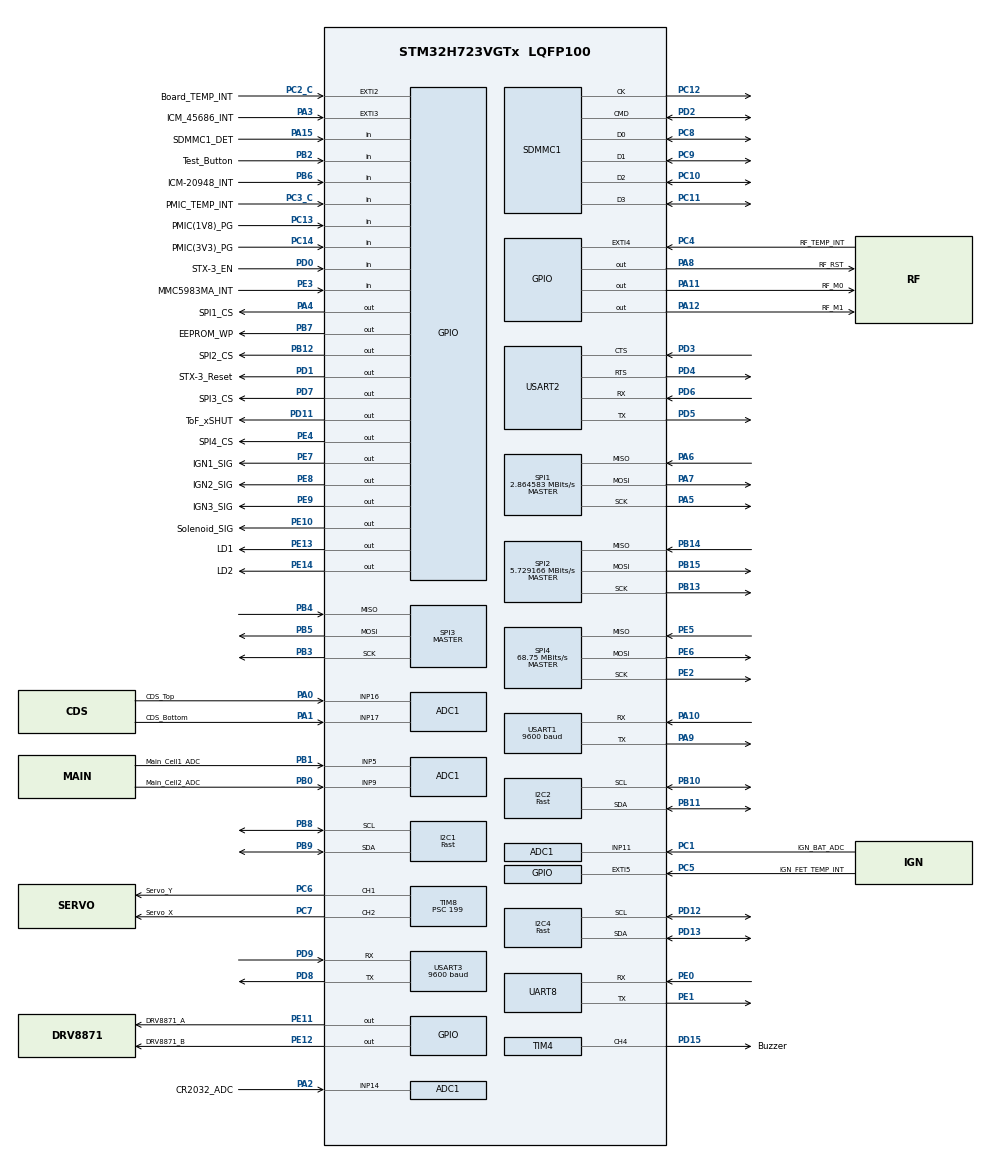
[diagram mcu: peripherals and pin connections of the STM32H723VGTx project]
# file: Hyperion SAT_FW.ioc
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ADC1.Channel-1\#ChannelRegularConversion=ADC_CHANNEL_5
ADC1.Channel-2\#ChannelRegularConversion=ADC_CHANNEL_9
ADC1.Channel-3\#ChannelRegularConversion=ADC_CHANNEL_11
ADC1.Channel-4\#ChannelRegularConversion=ADC_CHANNEL_14
ADC1.Channel-5\#ChannelRegularConversion=ADC_CHANNEL_16
ADC1.Channel-6\#ChannelRegularConversion=ADC_CHANNEL_17
ADC1.ClockPrescaler=ADC_CLOCK_ASYNC_DIV4
ADC1.ClockPrescalerADC3=ADC_CLOCK_ASYNC_DIV4
ADC1.ContinuousConvMode=ENABLE
ADC1.ConversionDataManagement=ADC_CONVERSIONDATA_DMA_CIRCULAR
ADC1.NbrOfConversion=6
ADC1.NbrOfConversionFlag=1
ADC1.OffsetNumber-1\#ChannelRegularConversion=ADC_OFFSET_NONE
ADC1.OffsetNumber-2\#ChannelRegularConversion=ADC_OFFSET_NONE
ADC1.OffsetNumber-3\#ChannelRegularConversion=ADC_OFFSET_NONE
ADC1.OffsetNumber-4\#ChannelRegularConversion=ADC_OFFSET_NONE
ADC1.OffsetNumber-5\#ChannelRegularConversion=ADC_OFFSET_NONE
ADC1.OffsetNumber-6\#ChannelRegularConversion=ADC_OFFSET_NONE
ADC1.OffsetSignedSaturation-1\#ChannelRegularConversion=DISABLE
ADC1.OffsetSignedSaturation-2\#ChannelRegularConversion=DISABLE
ADC1.OffsetSignedSaturation-3\#ChannelRegularConversion=DISABLE
ADC1.OffsetSignedSaturation-4\#ChannelRegularConversion=DISABLE
ADC1.OffsetSignedSaturation-5\#ChannelRegularConversion=DISABLE
ADC1.OffsetSignedSaturation-6\#ChannelRegularConversion=DISABLE
ADC1.Rank-1\#ChannelRegularConversion=1
ADC1.Rank-2\#ChannelRegularConversion=2
ADC1.Rank-3\#ChannelRegularConversion=3
ADC1.Rank-4\#ChannelRegularConversion=4
ADC1.Rank-5\#ChannelRegularConversion=5
ADC1.Rank-6\#ChannelRegularConversion=6
ADC1.SamplingTime-1\#ChannelRegularConversion=ADC_SAMPLETIME_387CYCLES_5
ADC1.SamplingTime-2\#ChannelRegularConversion=ADC_SAMPLETIME_387CYCLES_5
ADC1.SamplingTime-3\#ChannelRegularConversion=ADC_SAMPLETIME_387CYCLES_5
ADC1.SamplingTime-4\#ChannelRegularConversion=ADC_SAMPLETIME_387CYCLES_5
ADC1.SamplingTime-5\#ChannelRegularConversion=ADC_SAMPLETIME_387CYCLES_5
ADC1.SamplingTime-6\#ChannelRegularConversion=ADC_SAMPLETIME_387CYCLES_5
ADC1.master=1
ADC3.Channel-0\#ChannelRegularConversion=ADC_CHANNEL_TEMPSENSOR
ADC3.Channel-1\#ChannelRegularConversion=ADC_CHANNEL_VREFINT
ADC3.ClockPrescaler=ADC_CLOCK_ASYNC_DIV4
ADC3.ClockPrescalerADC3=ADC_CLOCK_ASYNC_DIV4
ADC3.ContinuousConvMode=ENABLE
ADC3.ConversionDataManagement=ADC_CONVERSIONDATA_DMA_CIRCULAR
ADC3.DMAContinuousRequests=ENABLE
ADC3.NbrOfConversion=2
ADC3.NbrOfConversionFlag=1
ADC3.OffsetNumber-0\#ChannelRegularConversion=ADC_OFFSET_NONE
ADC3.OffsetNumber-1\#ChannelRegularConversion=ADC_OFFSET_NONE
ADC3.OffsetSign-0\#ChannelRegularConversion=ADC3_OFFSET_SIGN_NEGATIVE
ADC3.OffsetSign-1\#ChannelRegularConversion=ADC3_OFFSET_SIGN_NEGATIVE
ADC3.Rank-0\#ChannelRegularConversion=1
ADC3.Rank-1\#ChannelRegularConversion=2
ADC3.SamplingTime-0\#ChannelRegularConversion=ADC3_SAMPLETIME_640CYCLES_5
ADC3.SamplingTime-1\#ChannelRegularConversion=ADC3_SAMPLETIME_640CYCLES_5
CORTEX_M7.CPU_DCache=Disabled
CORTEX_M7.CPU_ICache=Disabled
CORTEX_M7.MPU_Control=MPU_PRIVILEGED_DEFAULT
CORTEX_M7.default_mode_Activation=1
Dma.ADC1.0.Direction=DMA_PERIPH_TO_MEMORY
Dma.ADC1.0.EventEnable=DISABLE
Dma.ADC1.0.FIFOMode=DMA_FIFOMODE_DISABLE
Dma.ADC1.0.Instance=DMA1_Stream0
Dma.ADC1.0.MemDataAlignment=DMA_MDATAALIGN_HALFWORD
Dma.ADC1.0.MemInc=DMA_MINC_ENABLE
Dma.ADC1.0.Mode=DMA_CIRCULAR
Dma.ADC1.0.PeriphDataAlignment=DMA_PDATAALIGN_HALFWORD
Dma.ADC1.0.PeriphInc=DMA_PINC_DISABLE
Dma.ADC1.0.Polarity=HAL_DMAMUX_REQ_GEN_RISING
Dma.ADC1.0.Priority=DMA_PRIORITY_LOW
Dma.ADC1.0.RequestNumber=1
Dma.ADC1.0.SignalID=NONE
Dma.ADC1.0.SyncEnable=DISABLE
Dma.ADC1.0.SyncPolarity=HAL_DMAMUX_SYNC_NO_EVENT
Dma.ADC1.0.SyncRequestNumber=1
Dma.ADC1.0.SyncSignalID=NONE
Dma.ADC3.1.Direction=DMA_PERIPH_TO_MEMORY
Dma.ADC3.1.EventEnable=DISABLE
Dma.ADC3.1.FIFOMode=DMA_FIFOMODE_DISABLE
Dma.ADC3.1.Instance=DMA1_Stream1
Dma.ADC3.1.MemDataAlignment=DMA_MDATAALIGN_HALFWORD
Dma.ADC3.1.MemInc=DMA_MINC_ENABLE
Dma.ADC3.1.Mode=DMA_CIRCULAR
Dma.ADC3.1.PeriphDataAlignment=DMA_PDATAALIGN_HALFWORD
Dma.ADC3.1.PeriphInc=DMA_PINC_DISABLE
Dma.ADC3.1.Polarity=HAL_DMAMUX_REQ_GEN_RISING
Dma.ADC3.1.Priority=DMA_PRIORITY_LOW
Dma.ADC3.1.RequestNumber=1
Dma.ADC3.1.SignalID=NONE
Dma.ADC3.1.SyncEnable=DISABLE
Dma.ADC3.1.SyncPolarity=HAL_DMAMUX_SYNC_NO_EVENT
Dma.ADC3.1.SyncRequestNumber=1
Dma.ADC3.1.SyncSignalID=NONE
Dma.Request0=ADC1
Dma.Request1=ADC3
FATFS.BSP.number=1
FATFS.USE_DMA_CODE_SD=1
FATFS._MAX_SS=512
FATFS._USE_LFN=2
FATFS0.BSP.STBoard=false
FATFS0.BSP.api=Unknown
FATFS0.BSP.instance=PA15(JTDI)
FATFS0.BSP.ip=GPIO
FATFS0.BSP.mode=Input
FATFS0.BSP.name=Detect_SDIO
FATFS0.BSP.solution=PA15(JTDI)
FREERTOS.Tasks01=BootTask,24,512,StartBootTask,Default,NULL,Dynamic,NULL,NULL;sendDataTask,8,512,StartsendDataTask,Default,NULL,Dynamic,NULL,NULL;ADC_Task,8,128,StartADC_Task,Default,NULL,Dynamic,NULL,NULL;IMU_Task,24,256,StartIMU_Task,Default,NULL,Dynamic,NULL,NULL;GPS_Task,24,256,StartGPS_Task,Default,NULL,Dynamic,NULL,NULL;MS5611_Task,16,256,StartMS5611_Task,Default,NULL,Dynamic,NULL,NULL;INA219_Task,8,128,StartINA219_Task,Default,NULL,Dynamic,NULL,NULL;ReadTemp_Task,8,256,StartReadTemp_Task,Default,NULL,Dynamic,NULL,NULL;MainTask,40,1024,StartMainTask,Default,NULL,Dynamic,NULL,NULL
FREERTOS.configUSE_NEWLIB_REENTRANT=1
I2C1.I2C_Speed_Mode=I2C_Fast
I2C1.Timing=0x00D049FB
I2C2.CustomTiming=Disabled
I2C2.I2C_Speed_Mode=I2C_Fast
I2C2.Timing=0x00D049FB
I2C4.I2C_Speed_Mode=I2C_Fast
I2C4.Timing=0x00D049FB
Mcu.Family=STM32H7
Mcu.Name=STM32H723VGTx
Mcu.Package=LQFP100
NVIC.DMA1_Stream0_IRQn=true\:5\:0\:false\:false\:true\:true\:false\:true\:true
NVIC.DMA1_Stream1_IRQn=true\:5\:0\:false\:false\:true\:true\:false\:true\:true
NVIC.EXTI3_IRQn=true\:5\:0\:false\:true\:true\:1\:true\:true\:true\:true
NVIC.PriorityGroup=NVIC_PRIORITYGROUP_4
NVIC.SDMMC1_IRQn=true\:5\:0\:false\:false\:true\:true\:true\:true\:true
NVIC.TIM6_DAC_IRQn=true\:15\:0\:false\:false\:true\:false\:false\:true\:true
NVIC.TimeBase=TIM6_DAC_IRQn
NVIC.TimeBaseIP=TIM6
NVIC.USART1_IRQn=true\:10\:0\:true\:true\:true\:3\:true\:true\:true\:true
NVIC.USART3_IRQn=true\:6\:0\:true\:true\:true\:2\:true\:true\:true\:true
PA0.GPIO_Label=CDS_Top
PA0.Mode=IN16-Single-Ended
PA0.Signal=ADC1_INP16
PA1.GPIO_Label=CDS_Bottom
PA1.Mode=IN17-Single-Ended
PA1.Signal=ADC1_INP17
PA10.Mode=Asynchronous
PA10.Signal=USART1_RX
PA11.GPIO_Label=RF_M0
PA11.Signal=GPIO_Output
PA12.GPIO_Label=RF_M1
PA12.Signal=GPIO_Output
PA13(JTMS/SWDIO).Mode=Serial_Wire
PA13(JTMS/SWDIO).Signal=DEBUG_JTMS-SWDIO
PA14(JTCK/SWCLK).Mode=Serial_Wire
PA14(JTCK/SWCLK).Signal=DEBUG_JTCK-SWCLK
PA15(JTDI).GPIO_Label=SDMMC1_DET
PA15(JTDI).Signal=GPIO_Input
PA2.GPIO_Label=CR2032_ADC
PA2.Signal=ADCx_INP14
PA3.GPIO_Label=ICM_45686_INT
PA3.GPIO_ModeDefaultEXTI=GPIO_MODE_IT_FALLING
PA3.Signal=GPXTI3
PA4.GPIO_Label=SPI1_CS
PA4.GPIO_PuPd=GPIO_PULLUP
PA4.GPIO_Speed=GPIO_SPEED_FREQ_HIGH
PA4.PinState=GPIO_PIN_SET
PA4.Signal=GPIO_Output
PA5.GPIO_Speed=GPIO_SPEED_FREQ_HIGH
PA5.Mode=Full_Duplex_Master
PA5.Signal=SPI1_SCK
PA6.GPIO_Speed=GPIO_SPEED_FREQ_HIGH
PA6.Mode=Full_Duplex_Master
PA6.Signal=SPI1_MISO
PA7.GPIO_Speed=GPIO_SPEED_FREQ_HIGH
PA7.Mode=Full_Duplex_Master
PA7.Signal=SPI1_MOSI
PA8.GPIO_Label=RF_RST
PA8.Signal=GPIO_Output
PA9.Mode=Asynchronous
PA9.Signal=USART1_TX
PB0.GPIO_Label=Main_Cell2_ADC
PB0.Signal=ADCx_INP9
PB1.GPIO_Label=Main_Cell1_ADC
PB1.Signal=ADCx_INP5
PB10.GPIO_Pu=GPIO_PULLUP
PB10.GPIO_Speed=GPIO_SPEED_FREQ_HIGH
PB10.Mode=I2C
PB10.Signal=I2C2_SCL
PB11.GPIO_Pu=GPIO_PULLUP
PB11.GPIO_Speed=GPIO_SPEED_FREQ_HIGH
PB11.Mode=I2C
PB11.Signal=I2C2_SDA
PB12.GPIO_Label=SPI2_CS
PB12.GPIO_PuPd=GPIO_PULLUP
PB12.Signal=GPIO_Output
PB13.Mode=Full_Duplex_Master
PB13.Signal=SPI2_SCK
PB14.Mode=Full_Duplex_Master
PB14.Signal=SPI2_MISO
PB15.Mode=Full_Duplex_Master
PB15.Signal=SPI2_MOSI
PB2.GPIO_Label=Test_Button
PB2.Signal=GPIO_Input
PB3(JTDO/TRACESWO).Mode=Full_Duplex_Master
PB3(JTDO/TRACESWO).Signal=SPI3_SCK
PB4(NJTRST).Mode=Full_Duplex_Master
PB4(NJTRST).Signal=SPI3_MISO
PB5.Mode=Full_Duplex_Master
PB5.Signal=SPI3_MOSI
PB6.GPIO_Label=ICM-20948_INT
PB6.Signal=GPIO_Input
PB7.GPIO_Label=EEPROM_WP
PB7.PinState=GPIO_PIN_SET
PB7.Signal=GPIO_Output
PB8.Mode=I2C
PB8.Signal=I2C1_SCL
PB9.Mode=I2C
PB9.Signal=I2C1_SDA
PC1.GPIO_Label=IGN_BAT_ADC
PC1.Signal=ADCx_INP11
PC10.Mode=SD_4_bits_Wide_bus
PC10.Signal=SDMMC1_D2
PC11.Mode=SD_4_bits_Wide_bus
PC11.Signal=SDMMC1_D3
PC12.Mode=SD_4_bits_Wide_bus
PC12.Signal=SDMMC1_CK
PC13.GPIO_Label=PMIC(1V8)_PG
PC13.Signal=GPIO_Input
PC14-OSC32_IN.GPIO_Label=PMIC(3V3)_PG
PC14-OSC32_IN.Signal=GPIO_Input
PC2_C.GPIO_Label=Board_TEMP_INT
PC2_C.Signal=GPXTI2
PC3_C.GPIO_Label=PMIC_TEMP_INT
PC3_C.Signal=GPIO_Input
PC4.GPIO_Label=RF_TEMP_INT
PC4.Signal=GPXTI4
PC5.GPIO_Label=IGN_FET_TEMP_INT
PC5.Signal=GPXTI5
PC6.GPIO_Label=Servo_Y
PC6.Signal=S_TIM8_CH1
PC7.GPIO_Label=Servo_X
PC7.Signal=S_TIM8_CH2
PC8.Mode=SD_4_bits_Wide_bus
PC8.Signal=SDMMC1_D0
PC9.Mode=SD_4_bits_Wide_bus
PC9.Signal=SDMMC1_D1
PD0.GPIO_Label=STX-3_EN
PD0.Signal=GPIO_Input
PD1.GPIO_Label=STX-3_Reset
PD1.Signal=GPIO_Output
PD11.GPIO_Label=ToF_xSHUT
PD11.Signal=GPIO_Output
PD12.Mode=I2C
PD12.Signal=I2C4_SCL
PD13.Mode=I2C
PD13.Signal=I2C4_SDA
PD15.GPIO_Label=Buzzer
PD15.Signal=S_TIM4_CH4
PD2.Mode=SD_4_bits_Wide_bus
PD2.Signal=SDMMC1_CMD
PD3.Mode=CTS_RTS
PD3.Signal=USART2_CTS
PD4.Mode=CTS_RTS
PD4.Signal=USART2_RTS
PD5.Mode=Asynchronous
PD5.Signal=USART2_TX
PD6.Mode=Asynchronous
PD6.Signal=USART2_RX
PD7.GPIO_Label=SPI3_CS
PD7.Signal=GPIO_Output
PD8.Mode=Asynchronous
PD8.Signal=USART3_TX
PD9.Mode=Asynchronous
PD9.Signal=USART3_RX
PE0.Mode=Asynchronous
PE0.Signal=UART8_RX
PE1.Mode=Asynchronous
PE1.Signal=UART8_TX
PE10.GPIO_Label=Solenoid_SIG
PE10.Signal=GPIO_Output
PE11.GPIO_Label=DRV8871_A
PE11.Signal=GPIO_Output
PE12.GPIO_Label=DRV8871_B
PE12.Signal=GPIO_Output
PE13.GPIO_Label=LD1
PE13.Signal=GPIO_Output
PE14.GPIO_Label=LD2
PE14.Signal=GPIO_Output
PE2.Mode=Full_Duplex_Master
PE2.Signal=SPI4_SCK
PE3.GPIO_Label=MMC5983MA_INT
PE3.Signal=GPIO_Input
PE4.GPIO_Label=SPI4_CS
PE4.Signal=GPIO_Output
PE5.Mode=Full_Duplex_Master
PE5.Signal=SPI4_MISO
PE6.Mode=Full_Duplex_Master
PE6.Signal=SPI4_MOSI
PE7.GPIO_Label=IGN1_SIG
PE7.Signal=GPIO_Output
PE8.GPIO_Label=IGN2_SIG
PE8.Signal=GPIO_Output
PE9.GPIO_Label=IGN3_SIG
PE9.Signal=GPIO_Output
PH0-OSC_IN.Mode=HSE-External-Oscillator
PH0-OSC_IN.Signal=RCC_OSC_IN
PH1-OSC_OUT.Mode=HSE-External-Oscillator
PH1-OSC_OUT.Signal=RCC_OSC_OUT
ProjectManager.HeapSize=0x200
ProjectManager.StackSize=0x400
ProjectManager.TargetToolchain=STM32CubeIDE
RCC.ADCFreq_Value=96000000
RCC.APB1Freq_Value=137500000
RCC.APB2Freq_Value=137500000
RCC.APB3Freq_Value=137500000
RCC.APB4Freq_Value=137500000
RCC.CortexFreq_Value=550000000
RCC.D1PPRE=RCC_APB3_DIV2
RCC.D2PPRE1=RCC_APB1_DIV2
RCC.D2PPRE2=RCC_APB2_DIV2
RCC.D3PPRE=RCC_APB4_DIV2
RCC.DIVM1=3
RCC.DIVM2=1
RCC.DIVN1=137
RCC.DIVN2=16
RCC.DIVP1=1
RCC.DIVQ1=3
RCC.HCLKFreq_Value=275000000
RCC.HPRE=RCC_HCLK_DIV2
RCC.HSE_VALUE=12000000
RCC.PLL1_VCI_Range-AdvancedSettings=RCC_PLL1VCIRANGE_0
RCC.PLL1_VCO_SEL-AdvancedSettings=RCC_PLL1VCOMEDIUM
RCC.PLL2FRACN=0
RCC.PLL2_VCO_SEL-AdvancedSettings=RCC_PLL2VCOMEDIUM
RCC.PLL3FRACN=0
RCC.PLL3_VCO_SEL-AdvancedSettings=RCC_PLL3VCOMEDIUM
RCC.PLLFRACN=4096
RCC.PLLSourceVirtual=RCC_PLLSOURCE_HSE
RCC.SDMMC1CLockSelection=RCC_SDMMCCLKSOURCE_PLL2
RCC.SYSCLKFreq_VALUE=550000000
RCC.SYSCLKSource=RCC_SYSCLKSOURCE_PLLCLK
RCC.Tim1Mul=1
RCC.Tim2Mul=1
RCC.USBFreq_Value=183333333.33333334
SDMMC1.ClockDiv=2
SH.ADCx_INP11.0=ADC1_INP11,IN11-Single-Ended
SH.ADCx_INP14.0=ADC1_INP14,IN14-Single-Ended
SH.ADCx_INP5.0=ADC1_INP5,IN5-Single-Ended
SH.ADCx_INP9.0=ADC1_INP9,IN9-Single-Ended
SH.S_TIM4_CH4.0=TIM4_CH4,PWM Generation4 CH4
SH.S_TIM8_CH1.0=TIM8_CH1,PWM Generation1 CH1
SH.S_TIM8_CH2.0=TIM8_CH2,PWM Generation2 CH2
SPI1.BaudRatePrescaler=SPI_BAUDRATEPRESCALER_64
SPI1.CLKPhase=SPI_PHASE_2EDGE
SPI1.CLKPolarity=SPI_POLARITY_HIGH
SPI1.CalculateBaudRate=2.864583 MBits/s
SPI1.DataSize=SPI_DATASIZE_8BIT
SPI1.Direction=SPI_DIRECTION_2LINES
SPI1.Mode=SPI_MODE_MASTER
SPI1.VirtualType=VM_MASTER
SPI2.BaudRatePrescaler=SPI_BAUDRATEPRESCALER_32
SPI2.CalculateBaudRate=5.729166 MBits/s
SPI2.DataSize=SPI_DATASIZE_8BIT
SPI2.Direction=SPI_DIRECTION_2LINES
SPI2.Mode=SPI_MODE_MASTER
SPI2.VirtualType=VM_MASTER
SPI3.BaudRatePrescaler=SPI_BAUDRATEPRESCALER_2
SPI3.CalculateBaudRate=91.666664 MBits/s
SPI3.Direction=SPI_DIRECTION_2LINES
SPI3.Mode=SPI_MODE_MASTER
SPI3.VirtualType=VM_MASTER
SPI4.CalculateBaudRate=68.75 MBits/s
SPI4.Direction=SPI_DIRECTION_2LINES
SPI4.Mode=SPI_MODE_MASTER
SPI4.VirtualType=VM_MASTER
TIM4.AutoReloadPreload=TIM_AUTORELOAD_PRELOAD_ENABLE
TIM4.Channel-PWM\ Generation4\ CH4=TIM_CHANNEL_4
TIM4.OCFastMode_PWM-PWM\ Generation4\ CH4=TIM_OCFAST_ENABLE
TIM4.Period=99
TIM4.Prescaler=0
TIM4.Pulse-PWM\ Generation4\ CH4=50
TIM7.Prescaler=274
TIM8.Channel-PWM\ Generation1\ CH1=TIM_CHANNEL_1
TIM8.Channel-PWM\ Generation2\ CH2=TIM_CHANNEL_2
TIM8.Period=3029
TIM8.Prescaler=199
TIM8.Pulse-PWM\ Generation1\ CH1=1520
USART1.BaudRate=9600
USART1.VirtualMode-Asynchronous=VM_ASYNC
USART2.VirtualMode-Asynchronous=VM_ASYNC
USART3.BaudRate=9600
USART3.VirtualMode-Asynchronous=VM_ASYNC
VP_ADC3_TempSens_Input.Mode=IN-TempSens
VP_ADC3_Vref_Input.Mode=IN-Vrefint
VP_FATFS_VS_SDIO.Mode=SDIO
VP_FREERTOS_VS_CMSIS_V2.Mode=CMSIS_V2
VP_MEMORYMAP_VS_MEMORYMAP.Mode=CurAppReg
VP_SYS_VS_tim6.Mode=TIM6
VP_TIM4_VS_ClockSourceINT.Mode=Internal
VP_TIM7_VS_ClockSourceINT.Mode=Enable_Timer
VP_TIM8_VS_ClockSourceINT.Mode=Internal
board=custom

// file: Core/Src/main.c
/* USER CODE BEGIN Header */
/**
  ******************************************************************************
  * @file           : main.c
  * @brief          : Main program body
  ******************************************************************************
  * @attention
  *
  * Copyright (c) 2025 STMicroelectronics.
  * All rights reserved.
  *
  * This software is licensed under terms that can be found in the LICENSE file
  * in the root directory of this software component.
  * If no LICENSE file comes with this software, it is provided AS-IS.
  *
  ******************************************************************************
  */
/* USER CODE END Header */
#include "main.h"
#include "cmsis_os.h"
#include "adc.h"
#include "dma.h"
#include "fatfs.h"
#include "i2c.h"
#include "sdmmc.h"
#include "spi.h"
#include "tim.h"
#include "usart.h"
#include "gpio.h"

/* USER CODE BEGIN PD */
#define AS6221_Board_ADDR 0x48 << 1
#define AS6221_PMIC_ADDR 0x49 << 1
#define AS6221_IGNFET_ADDR 0x4B << 1

/* USER CODE END PD */

void SystemClock_Config(void);
void PeriphCommonClock_Config(void);
static void MPU_Config(void);
void MX_FREERTOS_Init(void);
static void MX_NVIC_Init(void);

int main(void)
{

  /* MPU Configuration--------------------------------------------------------*/
  MPU_Config();

  /* MCU Configuration--------------------------------------------------------*/

  /* Reset of all peripherals, Initializes the Flash interface and the Systick. */
  HAL_Init();

  /* Configure the system clock */
  SystemClock_Config();

  /* Configure the peripherals common clocks */
  PeriphCommonClock_Config();

  /* Initialize all configured peripherals */
  MX_GPIO_Init();
  MX_DMA_Init();
  MX_ADC1_Init();
  MX_I2C1_Init();
  MX_I2C2_Init();
  MX_SDMMC1_SD_Init();
  MX_SPI1_Init();
  MX_SPI2_Init();
  MX_SPI3_Init();
  MX_SPI4_Init();
  MX_TIM4_Init();
  MX_TIM8_Init();
  MX_UART8_Init();
  MX_USART1_UART_Init();
  MX_USART2_UART_Init();
  MX_USART3_UART_Init();
  MX_FATFS_Init();
  MX_ADC3_Init();
  MX_TIM7_Init();
  MX_I2C4_Init();

  /* Initialize interrupts */
  MX_NVIC_Init();
  /* USER CODE BEGIN 2 */

//  AS6221_t as6221[NUM_SENSORS];
//
//    as6221[0].address = AS6221_Board_ADDR;
//    as6221[0].CR = ConvPer125ms;
//    as6221[0].CF = Quadruple;
//    as6221[0].SM = false;
//    as6221[0].IM = false;
//    as6221[0].POL = false;
//    as6221[0].SS = false;
//
//    as6221[1] = as6221[0];
//    as6221[2] = as6221[0];
//
//    as6221[1].address = AS6221_PMIC_ADDR;
//    as6221[2].address = AS6221_IGNFET_ADDR;
//
//    for (int i = 0; i < NUM_SENSORS; i++) {
//  	  if (AS6221_Init(&as6221[i]) != AS6221_ERROR_NONE) {
//  		  printf("Failed Init %d\t", i + 1);
//  		  printf("Error Code: %d\n", AS6221_GetLastError());
//  	  }
//    }

//  BYTE buf[32] = "I Love You!";
//  uint32_t bw, br;
//  /* 1. SD 카드 마운트 ------------------------------------------------------ */
//  retSD = f_mount(&SDFatFS, SDPath, 1); /* 1=즉시 마운트 */
//  if (retSD != FR_OK) { LED_ERR(); printf("mount error %d\r\n", retSD); Error_Handler(); }
//  LED_OK(); HAL_Delay(500); LED_OFF();
//
//  retSD = f_open(&SDFile, "0:/jmh8231.txt", FA_CREATE_ALWAYS | FA_WRITE);
//  if (retSD != FR_OK) {
//	  LED_ERR();
//	  printf("f_open Error: %d\n", retSD);
//  }
//  f_write(&SDFile, buf, sizeof(buf), &bw);
//  f_close(&SDFile);
//  LED_OK();
//  HAL_Delay(1000);
//  LED_OFF();

//  HAL_GPIO_WritePin(EEPROM_WP_GPIO_Port, EEPROM_WP_Pin, GPIO_PIN_RESET);
//  HAL_Delay(10);
//  HAL_I2C_Mem_Write(&hi2c1, 0xA0, 0x00, I2C_MEMADD_SIZE_8BIT, &buf_write[0], 16, 1);
//  HAL_GPIO_WritePin(EEPROM_WP_GPIO_Port, EEPROM_WP_Pin, GPIO_PIN_SET);
//
//
//  HAL_Delay(10);
//  HAL_I2C_Mem_Read(&hi2c1, 0xA0, 0x00, I2C_MEMADD_SIZE_8BIT, &buf_read[0], 16, 1);
//
//  for(int i = 0; i < 16; i++)
//	  printf("Index: %d\t\tData: 0x%X\n", i, buf_read[i]);
//
//  DS3231_Init(&hi2c1);
//
//  DS3231_SetFullDate(2, 8, 6, 2025);
//  DS3231_SetFullTime(17, 34, 00);

  // ICM-45686 초기화
//  int32_t result = icm45686_init(&imu_device);
//  if (result != INV_IMU_OK) {
//      // 초기화 실패 처리
//      while(1) {
//          // 에러 LED 점멸 등
//    	  HAL_GPIO_TogglePin(LD1_GPIO_Port, LD1_Pin);
//    	  HAL_Delay(1000);
//      }
//  }

//  run_whoami_test();

  /* USER CODE END 2 */

  /* Init scheduler */
  osKernelInitialize();  /* Call init function for freertos objects (in cmsis_os2.c) */
  MX_FREERTOS_Init();

  /* Start scheduler */
  osKernelStart();

  /* We should never get here as control is now taken by the scheduler */

  /* Infinite loop */
  /* USER CODE BEGIN WHILE */
  while (1)
  {
//      uint8_t h = DS3231_GetHour();
//      uint8_t m = DS3231_GetMinute();
//      uint8_t s = DS3231_GetSecond();
//
//      printf("%02u:%02u:%02u\r\n", h, m, s);
//
//      int8_t temp = DS3231_GetTemperatureInteger();
//      printf("DS3231 Temp: %d\n", temp);
//
//      HAL_Delay(1000);

//	  if (ICM45686_DataReady())
//		{
//			if (ICM45686_ReadScaledData(&s) == HAL_OK)
//			{
//				printf("%.2f, %.2f, %.2f\n", s.accel_x, s.accel_y, s.accel_z);
//				printf("%.2f, %.2f, %.2f\n", s.gyro_x, s.gyro_y, s.gyro_z);
//			}
//			HAL_Delay(10);
//		}

    /* USER CODE END WHILE */

  }
}

void SystemClock_Config(void)
{
  RCC_OscInitTypeDef RCC_OscInitStruct = {0};
  RCC_ClkInitTypeDef RCC_ClkInitStruct = {0};

  /** Supply configuration update enable
  */
  HAL_PWREx_ConfigSupply(PWR_LDO_SUPPLY);

  /** Configure the main internal regulator output voltage
  */
  __HAL_PWR_VOLTAGESCALING_CONFIG(PWR_REGULATOR_VOLTAGE_SCALE0);

  while(!__HAL_PWR_GET_FLAG(PWR_FLAG_VOSRDY)) {}

  /** Initializes the RCC Oscillators according to the specified parameters
  * in the RCC_OscInitTypeDef structure.
  */
  RCC_OscInitStruct.OscillatorType = RCC_OSCILLATORTYPE_HSE;
  RCC_OscInitStruct.HSEState = RCC_HSE_ON;
  RCC_OscInitStruct.PLL.PLLState = RCC_PLL_ON;
  RCC_OscInitStruct.PLL.PLLSource = RCC_PLLSOURCE_HSE;
  RCC_OscInitStruct.PLL.PLLM = 3;
  RCC_OscInitStruct.PLL.PLLN = 137;
  RCC_OscInitStruct.PLL.PLLP = 1;
  RCC_OscInitStruct.PLL.PLLQ = 3;
  RCC_OscInitStruct.PLL.PLLR = 2;
  RCC_OscInitStruct.PLL.PLLRGE = RCC_PLL1VCIRANGE_2;
  RCC_OscInitStruct.PLL.PLLVCOSEL = RCC_PLL1VCOWIDE;
  RCC_OscInitStruct.PLL.PLLFRACN = 4096;
  if (HAL_RCC_OscConfig(&RCC_OscInitStruct) != HAL_OK)
  {
    Error_Handler();
  }

  /** Initializes the CPU, AHB and APB buses clocks
  */
  RCC_ClkInitStruct.ClockType = RCC_CLOCKTYPE_HCLK|RCC_CLOCKTYPE_SYSCLK
                              |RCC_CLOCKTYPE_PCLK1|RCC_CLOCKTYPE_PCLK2
                              |RCC_CLOCKTYPE_D3PCLK1|RCC_CLOCKTYPE_D1PCLK1;
  RCC_ClkInitStruct.SYSCLKSource = RCC_SYSCLKSOURCE_PLLCLK;
  RCC_ClkInitStruct.SYSCLKDivider = RCC_SYSCLK_DIV1;
  RCC_ClkInitStruct.AHBCLKDivider = RCC_HCLK_DIV2;
  RCC_ClkInitStruct.APB3CLKDivider = RCC_APB3_DIV2;
  RCC_ClkInitStruct.APB1CLKDivider = RCC_APB1_DIV2;
  RCC_ClkInitStruct.APB2CLKDivider = RCC_APB2_DIV2;
  RCC_ClkInitStruct.APB4CLKDivider = RCC_APB4_DIV2;

  if (HAL_RCC_ClockConfig(&RCC_ClkInitStruct, FLASH_LATENCY_3) != HAL_OK)
  {
    Error_Handler();
  }
}

void PeriphCommonClock_Config(void)
{
  RCC_PeriphCLKInitTypeDef PeriphClkInitStruct = {0};

  /** Initializes the peripherals clock
  */
  PeriphClkInitStruct.PeriphClockSelection = RCC_PERIPHCLK_ADC|RCC_PERIPHCLK_SDMMC;
  PeriphClkInitStruct.PLL2.PLL2M = 1;
  PeriphClkInitStruct.PLL2.PLL2N = 16;
  PeriphClkInitStruct.PLL2.PLL2P = 2;
  PeriphClkInitStruct.PLL2.PLL2Q = 2;
  PeriphClkInitStruct.PLL2.PLL2R = 2;
  PeriphClkInitStruct.PLL2.PLL2RGE = RCC_PLL2VCIRANGE_3;
  PeriphClkInitStruct.PLL2.PLL2VCOSEL = RCC_PLL2VCOWIDE;
  PeriphClkInitStruct.PLL2.PLL2FRACN = 0;
  PeriphClkInitStruct.SdmmcClockSelection = RCC_SDMMCCLKSOURCE_PLL2;
  PeriphClkInitStruct.AdcClockSelection = RCC_ADCCLKSOURCE_PLL2;
  if (HAL_RCCEx_PeriphCLKConfig(&PeriphClkInitStruct) != HAL_OK)
  {
    Error_Handler();
  }
}

/**
  * @brief NVIC Configuration.
  * @retval None
  */
static void MX_NVIC_Init(void)
{
  /* EXTI3_IRQn interrupt configuration */
  HAL_NVIC_SetPriority(EXTI3_IRQn, 5, 0);
  HAL_NVIC_EnableIRQ(EXTI3_IRQn);
  /* USART3_IRQn interrupt configuration */
  HAL_NVIC_SetPriority(USART3_IRQn, 6, 0);
  HAL_NVIC_EnableIRQ(USART3_IRQn);
  /* USART1_IRQn interrupt configuration */
  HAL_NVIC_SetPriority(USART1_IRQn, 10, 0);
  HAL_NVIC_EnableIRQ(USART1_IRQn);
}

 /* MPU Configuration */

void MPU_Config(void)
{
  MPU_Region_InitTypeDef MPU_InitStruct = {0};

  /* Disables the MPU */
  HAL_MPU_Disable();

  /** Initializes and configures the Region and the memory to be protected
  */
  MPU_InitStruct.Enable = MPU_REGION_ENABLE;
  MPU_InitStruct.Number = MPU_REGION_NUMBER0;
  MPU_InitStruct.BaseAddress = 0x0;
  MPU_InitStruct.Size = MPU_REGION_SIZE_4GB;
  MPU_InitStruct.SubRegionDisable = 0x87;
  MPU_InitStruct.TypeExtField = MPU_TEX_LEVEL0;
  MPU_InitStruct.AccessPermission = MPU_REGION_NO_ACCESS;
  MPU_InitStruct.DisableExec = MPU_INSTRUCTION_ACCESS_DISABLE;
  MPU_InitStruct.IsShareable = MPU_ACCESS_SHAREABLE;
  MPU_InitStruct.IsCacheable = MPU_ACCESS_NOT_CACHEABLE;
  MPU_InitStruct.IsBufferable = MPU_ACCESS_NOT_BUFFERABLE;

  HAL_MPU_ConfigRegion(&MPU_InitStruct);
  /* Enables the MPU */
  HAL_MPU_Enable(MPU_PRIVILEGED_DEFAULT);

}

void HAL_TIM_PeriodElapsedCallback(TIM_HandleTypeDef *htim)
{
  if (htim->Instance == TIM6)
  {
    HAL_IncTick();
  }
}

void Error_Handler(void)
{
  /* USER CODE BEGIN Error_Handler_Debug */
  /* User can add his own implementation to report the HAL error return state */
  __disable_irq();
  while (1)
  {
	  HAL_GPIO_TogglePin(LD1_GPIO_Port, LD1_Pin);
	  HAL_Delay(100);
  }
  /* USER CODE END Error_Handler_Debug */
}

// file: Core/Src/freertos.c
/* USER CODE BEGIN Header */
/**
 ******************************************************************************
 * File Name          : freertos.c
 * Description        : Code for freertos applications
 ******************************************************************************
 * @attention
 *
 * Copyright (c) 2025 STMicroelectronics.
 * All rights reserved.
 *
 * This software is licensed under terms that can be found in the LICENSE file
 * in the root directory of this software component.
 * If no LICENSE file comes with this software, it is provided AS-IS.
 *
 ******************************************************************************
 */
/* USER CODE END Header */

#include "FreeRTOS.h"
#include "task.h"
#include "main.h"
#include "cmsis_os.h"

/* USER CODE BEGIN Includes */
#include "driver_ms5611_basic.h"
#include <stdio.h>
#include <math.h>
#include "AS6221.h"
#include "DS3231.h"

#include "ICM45686.h"

#include "Data.h"
#include "adc.h"
#include "spi.h"
#include "tim.h"
#include "LoRa.h"
#include "INA219.h"
#include "i2c.h"
#include "usart.h"
#include <math.h>
#include <string.h>
#include <stdint.h>

/* USER CODE END Includes */

/* USER CODE BEGIN PD */
#define AS6221_Board_ADDR 0x48 << 1
#define AS6221_PMIC_ADDR 0x49 << 1
#define AS6221_LoRa_ADDR 0x4A << 1
#define AS6221_IGNFET_ADDR 0x4B << 1
#define NUM_SENSORS 4

/* USER CODE END PD */

/* USER CODE BEGIN PM */
int _write(int file, char* p, int len){
	HAL_UART_Transmit(&huart1, p, len, HAL_MAX_DELAY);
	return len;
}

/* USER CODE END PM */

/* USER CODE BEGIN Variables */
adcData adcdata;
uint16_t adc1_val[6];
uint16_t adc3_val[2];
icm45686Data icm45686;
ms5611Data ms5611;
ina219Data ina219_main;
ina219Data ina219_ign;
AS6221 as6221[NUM_SENSORS];
float CPU_Temp = 0;

uint8_t m10s_rx_buf[36];
volatile uint8_t m10s_rx_cplt_flag = 0;
volatile uint8_t rx3_data;
volatile uint8_t rx1_data;

volatile uint8_t Decoupling_flag = false;
volatile uint8_t forceING = false;

gpsData gps;

// 임무 상태 변수들
bool cansat_ejected = false;
bool hyperion_separated = false;
bool second_propellant_ignited = false;
bool evasive_maneuver_done = false;
bool max_altitude_reached = false;
bool parachute_ejected = false;
static float prev_altitude_for_parachute = 0.0f;

/* USER CODE END Variables */
/* Definitions for BootTask */
osThreadId_t BootTaskHandle;
const osThreadAttr_t BootTask_attributes = {
  .name = "BootTask",
  .stack_size = 512 * 4,
  .priority = (osPriority_t) osPriorityNormal,
};
/* Definitions for sendDataTask */
osThreadId_t sendDataTaskHandle;
const osThreadAttr_t sendDataTask_attributes = {
  .name = "sendDataTask",
  .stack_size = 512 * 4,
  .priority = (osPriority_t) osPriorityLow,
};
/* Definitions for ADC_Task */
osThreadId_t ADC_TaskHandle;
const osThreadAttr_t ADC_Task_attributes = {
  .name = "ADC_Task",
  .stack_size = 128 * 4,
  .priority = (osPriority_t) osPriorityLow,
};
/* Definitions for IMU_Task */
osThreadId_t IMU_TaskHandle;
const osThreadAttr_t IMU_Task_attributes = {
  .name = "IMU_Task",
  .stack_size = 256 * 4,
  .priority = (osPriority_t) osPriorityNormal,
};
/* Definitions for GPS_Task */
osThreadId_t GPS_TaskHandle;
const osThreadAttr_t GPS_Task_attributes = {
  .name = "GPS_Task",
  .stack_size = 256 * 4,
  .priority = (osPriority_t) osPriorityNormal,
};
/* Definitions for MS5611_Task */
osThreadId_t MS5611_TaskHandle;
const osThreadAttr_t MS5611_Task_attributes = {
  .name = "MS5611_Task",
  .stack_size = 256 * 4,
  .priority = (osPriority_t) osPriorityBelowNormal,
};
/* Definitions for INA219_Task */
osThreadId_t INA219_TaskHandle;
const osThreadAttr_t INA219_Task_attributes = {
  .name = "INA219_Task",
  .stack_size = 128 * 4,
  .priority = (osPriority_t) osPriorityLow,
};
/* Definitions for ReadTemp_Task */
osThreadId_t ReadTemp_TaskHandle;
const osThreadAttr_t ReadTemp_Task_attributes = {
  .name = "ReadTemp_Task",
  .stack_size = 256 * 4,
  .priority = (osPriority_t) osPriorityLow,
};
/* Definitions for MainTask */
osThreadId_t MainTaskHandle;
const osThreadAttr_t MainTask_attributes = {
  .name = "MainTask",
  .stack_size = 1024 * 4,
  .priority = (osPriority_t) osPriorityHigh,
};

/* USER CODE BEGIN FunctionPrototypes */
uint8_t ubx_checksum(uint8_t *payload, uint16_t length);
void M10S_UBX_POSLLH_Parsing(unsigned char* data, gpsData* gps);
void M10S_TransmitData(unsigned char* data, unsigned len);
uint16_t CRC16_CCITT(const uint8_t *data, uint16_t length);
void CRC16_CCITT_Split(const uint8_t *data, uint16_t length,
                       uint8_t *high, uint8_t *low);

/* USER CODE END FunctionPrototypes */

void StartBootTask(void *argument);
void StartsendDataTask(void *argument);
void StartADC_Task(void *argument);
void StartIMU_Task(void *argument);
void StartGPS_Task(void *argument);
void StartMS5611_Task(void *argument);
void StartINA219_Task(void *argument);
void StartReadTemp_Task(void *argument);
void StartMainTask(void *argument);

void MX_FREERTOS_Init(void); /* (MISRA C 2004 rule 8.1) */

void MX_FREERTOS_Init(void) {

  /* Create the thread(s) */
  /* creation of BootTask */
  BootTaskHandle = osThreadNew(StartBootTask, NULL, &BootTask_attributes);

}

void StartBootTask(void *argument)
{
  /* USER CODE BEGIN StartBootTask */
	HAL_UART_Receive_IT(&huart1, &rx1_data, 1);
	HAL_UART_Receive_IT(&huart3, &rx3_data, 1);

    HAL_GPIO_WritePin(GPIOE, GPIO_PIN_11, GPIO_PIN_SET); // 전자석 On
    HAL_GPIO_WritePin(GPIOE, GPIO_PIN_12, GPIO_PIN_RESET); // 전자석 On

	if (ICM45686_Init(&hspi1) == HAL_OK) {
		IMU_TaskHandle = osThreadNew(StartIMU_Task, NULL, &IMU_Task_attributes);
	}
	if (ms5611_basic_init(MS5611_INTERFACE_SPI, MS5611_ADDRESS_CSB_0) == 0) {
		MS5611_TaskHandle = osThreadNew(StartMS5611_Task, NULL,
				&MS5611_Task_attributes);
	}
	if (HAL_ADC_Start_DMA(&hadc1, &adc1_val[0], 6) == HAL_OK) {
		ADC_TaskHandle = osThreadNew(StartADC_Task, NULL, &ADC_Task_attributes);
	}
	if (INA219_Init(&ina219_main, &hi2c2, 0x40) == HAL_OK && INA219_Init(&ina219_ign, &hi2c2, 0x41) == HAL_OK) {
		INA219_setCalibration_32V_30A_001R(&ina219_ign);
		INA219_TaskHandle = osThreadNew(StartINA219_Task, NULL, &INA219_Task_attributes);
	}

	as6221[0].address = AS6221_Board_ADDR;
	as6221[0].CR = ConvPer125ms;
	as6221[0].CF = Quadruple;
	as6221[0].SM = false;
	as6221[0].IM = false;
	as6221[0].POL = false;
	as6221[0].SS = false;

	as6221[1] = as6221[0];
	as6221[2] = as6221[0];
	as6221[3] = as6221[0];

	as6221[1].address = AS6221_PMIC_ADDR;
	as6221[2].address = AS6221_LoRa_ADDR;
	as6221[3].address = AS6221_IGNFET_ADDR;

	uint8_t count = 0;

	for (int i = 0; i < NUM_SENSORS; i++) {
		if (AS6221_Init(&as6221[i]) != AS6221_ERROR_NONE) {
			count++;
		}
	}

	HAL_ADCEx_Calibration_Start(&hadc3, ADC_CALIB_OFFSET, ADC_SINGLE_ENDED);
	if (count < 4 && HAL_ADC_Start_DMA(&hadc3, &adc3_val[0], 2) == HAL_OK)
		ReadTemp_TaskHandle = osThreadNew(StartReadTemp_Task, NULL,
				&ReadTemp_Task_attributes);

	sendDataTaskHandle = osThreadNew(StartsendDataTask, NULL,
			&sendDataTask_attributes);
	GPS_TaskHandle = osThreadNew(StartGPS_Task, NULL, &GPS_Task_attributes);
	MainTaskHandle = osThreadNew(StartMainTask, NULL, &MainTask_attributes);

	HAL_TIM_PWM_Start(&htim4, TIM_CHANNEL_4);
	TIM4->PSC = 1199;
	osDelay(100);
	TIM4->PSC = 799;
	osDelay(100);
	TIM4->PSC = 599;
	osDelay(150);
	HAL_TIM_PWM_Stop(&htim4, TIM_CHANNEL_4);

	// BootTask 종료
	vTaskDelete(NULL); // Worker Task 삭제
  /* USER CODE END StartBootTask */
}

void StartsendDataTask(void *argument)
{
  /* USER CODE BEGIN StartsendDataTask */

	/* Infinite loop */
	for (;;) {
		uint8_t F_data[8] = {0};

		uint8_t altitude_L = 0;
		uint8_t altitude_H = 0;
		uint8_t ck_L, ck_H = 0;

		altitude_H = (ms5611.altitude >> 8) & 0xFF;  // 상위 8비트
	    altitude_L = ms5611.altitude & 0xFF;          // 하위 8비트

	    F_data[0] = 'H';
	    F_data[1] = 'S';
	    F_data[2] = 10;
	    F_data[3] = 2;
	    F_data[4] = altitude_H;
	    F_data[5] = altitude_L;
	    CRC16_CCITT_Split(&F_data[2], 4, ck_H, ck_L);
	    F_data[6] = ck_H;
	    F_data[7] = ck_L;

	    for(int i = 0; i < sizeof(F_data); i++) {
	    	printf("%d", F_data[i]);

	    	if(i < sizeof(F_data) - 1)
	    		printf(",");
	    		osDelay(10);
	    }
	    printf("\n");

		ck_L = 0;
		ck_H = 0;

		uint8_t A_data[38] = {0};

				// 가속도, 자이로, GPS 데이터를 바이트로 변환
				int16_t i_accel_x = (int16_t)icm45686.accel_x;
				uint16_t f_accel_x = (uint16_t)((icm45686.accel_x - i_accel_x) * 10000);
				int16_t i_accel_y = (int16_t)icm45686.accel_y;
				uint16_t f_accel_y = (uint16_t)((icm45686.accel_y - i_accel_y) * 10000);
				int16_t i_accel_z = (int16_t)icm45686.accel_z;
				uint16_t f_accel_z = (uint16_t)((icm45686.accel_z - i_accel_z) * 10000);

				int16_t i_gyro_x = (int16_t)icm45686.gyro_x;
				uint16_t f_gyro_x = (uint16_t)((icm45686.gyro_x - i_gyro_x) * 10000);
				int16_t i_gyro_y = (int16_t)icm45686.gyro_y;
				uint16_t f_gyro_y = (uint16_t)((icm45686.gyro_y - i_gyro_y) * 10000);
				int16_t i_gyro_z = (int16_t)icm45686.gyro_z;
				uint16_t f_gyro_z = (uint16_t)((icm45686.gyro_z - i_gyro_z) * 10000);

				int16_t i_gps_lat = (int16_t)gps.lat_f64;
				uint16_t f_gps_lat = (uint16_t)((gps.lat_f64 - i_gps_lat) * 1000000);
				int16_t i_gps_lon = (int16_t)gps.lon_f64;
				uint16_t f_gps_lon = (uint16_t)((gps.lon_f64 - i_gps_lon) * 1000000);

				A_data[0] = 'H';
				A_data[1] = 'S';
				A_data[2] = 11;
				A_data[3] = 32;

				A_data[4] = (i_accel_x >> 8) & 0xFF;
				A_data[5] = i_accel_x & 0xFF;
				A_data[6] = (f_accel_x >> 8) & 0xFF;
				A_data[7] = f_accel_x & 0xFF;
				A_data[8] = (i_accel_y >> 8) & 0xFF;
				A_data[9] = i_accel_y & 0xFF;
				A_data[10] = (f_accel_y >> 8) & 0xFF;
				A_data[11] = f_accel_y & 0xFF;
				A_data[12] = (i_accel_z >> 8) & 0xFF;
				A_data[13] = i_accel_z & 0xFF;
				A_data[14] = (f_accel_z >> 8) & 0xFF;
				A_data[15] = f_accel_z & 0xFF;

				A_data[16] = (i_gyro_x >> 8) & 0xFF;
				A_data[17] = i_gyro_x & 0xFF;
				A_data[18] = (f_gyro_x >> 8) & 0xFF;
				A_data[19] = f_gyro_x & 0xFF;
				A_data[20] = (i_gyro_y >> 8) & 0xFF;
				A_data[21] = i_gyro_y & 0xFF;
				A_data[22] = (f_gyro_y >> 8) & 0xFF;
				A_data[23] = f_gyro_y & 0xFF;
				A_data[24] = (i_gyro_z >> 8) & 0xFF;
				A_data[25] = i_gyro_z & 0xFF;
				A_data[26] = (f_gyro_z >> 8) & 0xFF;
				A_data[27] = f_gyro_z & 0xFF;

				A_data[28] = (i_gps_lat >> 8) & 0xFF;
				A_data[29] = i_gps_lat & 0xFF;
				A_data[30] = (f_gps_lat >> 8) & 0xFF;
				A_data[31] = f_gps_lat & 0xFF;
				A_data[32] = (i_gps_lon >> 8) & 0xFF;
				A_data[33] = i_gps_lon & 0xFF;
				A_data[34] = (f_gps_lon >> 8) & 0xFF;
				A_data[35] = f_gps_lon & 0xFF;

				CRC16_CCITT_Split(&A_data[2], 34, ck_H, ck_L);
				A_data[36] = ck_H;
				A_data[37] = ck_L;

				for(int i = 0; i < sizeof(A_data); i++) {
					printf("%d", A_data[i]);
					if(i < sizeof(A_data) - 1)
						printf(",");
						osDelay(10);
				}
				printf("\n");

				uint8_t S_data[33] = {0};

				// 센서 데이터를 바이트로 변환
				uint8_t i_main_cell1 = (uint8_t)adcdata.Main_BAT_Cell1;
				uint8_t f_main_cell1 = (uint8_t)((adcdata.Main_BAT_Cell1 - i_main_cell1) * 100);
				uint8_t i_main_cell2 = (uint8_t)adcdata.Main_BAT_Cell2;
				uint8_t f_main_cell2 = (uint8_t)((adcdata.Main_BAT_Cell2 - i_main_cell2) * 100);

				uint8_t i_ign_v = (uint8_t)adcdata.IGN_BAT;
				uint8_t f_ign_v = (uint8_t)((adcdata.IGN_BAT - i_ign_v) * 100);

				uint8_t i_cpu_temp = (uint8_t)CPU_Temp;
				uint8_t f_cpu_temp = (uint8_t)((CPU_Temp - i_cpu_temp) * 100);

				uint8_t i_board_temp = (uint8_t)as6221[0].Temp;
				uint8_t f_board_temp = (uint8_t)((as6221[0].Temp - i_board_temp) * 100);

				uint8_t i_pmic_temp = (uint8_t)as6221[1].Temp;
				uint8_t f_pmic_temp = (uint8_t)((as6221[1].Temp - i_pmic_temp) * 100);

				uint8_t i_lora_temp = (uint8_t)as6221[2].Temp;
				uint8_t f_lora_temp = (uint8_t)((as6221[2].Temp - i_lora_temp) * 100);

				uint8_t i_ign_fet_temp = (uint8_t)as6221[3].Temp;
				uint8_t f_ign_fet_temp = (uint8_t)((as6221[3].Temp - i_ign_fet_temp) * 100);

				S_data[0] = 'H';
				S_data[1] = 'S';
				S_data[2] = 12;
				S_data[3] = 27;

				S_data[4] = i_main_cell1;
				S_data[5] = f_main_cell1;
				S_data[6] = i_main_cell2;
				S_data[7] = f_main_cell2;
				S_data[8] = (ina219_main.current >> 8) & 0xFF;
				S_data[9] = ina219_main.current & 0xFF;
				S_data[10] = ina219_main.battery_level;
				S_data[11] = i_ign_v;
				S_data[12] = f_ign_v;
				S_data[13] = ina219_ign.current;
				S_data[14] = ina219_ign.battery_level;
				S_data[15] = i_cpu_temp;
				S_data[16] = f_cpu_temp;
				S_data[17] = i_board_temp;
				S_data[18] = f_board_temp;
				S_data[19] = i_pmic_temp;
				S_data[20] = f_pmic_temp;
				S_data[21] = i_lora_temp;
				S_data[22] = f_lora_temp;
				S_data[23] = i_ign_fet_temp;
				S_data[24] = f_ign_fet_temp;
				S_data[25] = (adcdata.CR2032_BAT > 2.5) ? 1 : 0; // 3.3V PG
				S_data[26] = (adcdata.CR2032_BAT > 1.5) ? 1 : 0; // 1.8V PG (임시 값, 실제 1.8V 레귤레이터 PG 데이터 필요)
				S_data[27] = (adcdata.CDS_Top >> 8) & 0xFF;
				S_data[28] = adcdata.CDS_Top & 0xFF;
				S_data[29] = (adcdata.CDS_Bottom >> 8) & 0xFF;
				S_data[30] = adcdata.CDS_Bottom & 0xFF;

				CRC16_CCITT_Split(&S_data[2], 29, ck_H, ck_L);
				S_data[31] = ck_H;
				S_data[32] = ck_L;

				for(int i = 0; i < sizeof(S_data); i++) {
					printf("%d", S_data[i]);
					if(i < sizeof(S_data) - 1)
						printf(",");
						osDelay(10);
				}
				printf("\n");

				osDelay(2000);
	}
  /* USER CODE END StartsendDataTask */
}

void StartADC_Task(void *argument)
{
  /* USER CODE BEGIN StartADC_Task */
#define ADC_RESOLUTION 65535.0f

	/* Infinite loop */
	for (;;) {
		adcdata.Main_BAT_Cell1 = (((float) adc1_val[0] / ADC_RESOLUTION) * 3.3)
				* 4.5;
		adcdata.Main_BAT_Cell2 = (((float) adc1_val[1] / ADC_RESOLUTION) * 3.3)
				* 4.5;
		adcdata.IGN_BAT = (((float) adc1_val[2] / ADC_RESOLUTION) * 3.3) * 4.5;
		adcdata.CR2032_BAT = (((float) adc1_val[3] / ADC_RESOLUTION) * 3.3) * 2;
		adcdata.CDS_Top = adc1_val[4];
		adcdata.CDS_Bottom = adc1_val[5];

		osDelay(100);
	}
  /* USER CODE END StartADC_Task */
}

void StartIMU_Task(void *argument)
{
  /* USER CODE BEGIN StartIMU_Task */
    static uint32_t last_impact_ms = 0;
    // 임계값은 실제 비행 데이터 로그를 분석하여 최적의 값을 찾아야 합니다.
    #define ACCEL_IMPACT_THRESHOLD_G   30.0f   // 충격 감지를 위한 가속도 임계값 (G)
    #define GYRO_IMPACT_THRESHOLD_DPS  2000.0f  // 충격 감지를 위한 각속도 임계값 (degrees per second)
    #define IMPACT_DEBOUNCE_MS         500     // 이벤트 감지 후 안정화 시간 (조금 더 길게 설정)

    /* Infinite loop */
    for (;;) {
        if (ICM45686_DataReady()) {
            ICM45686_ReadScaledData(&icm45686);

            // 1. 가속도 크기 계산
            float accel_mag = sqrtf(icm45686.accel_x * icm45686.accel_x +
                                    icm45686.accel_y * icm45686.accel_y +
                                    icm45686.accel_z * icm45686.accel_z);

            // 2. 각속도 크기 계산
            float gyro_mag = sqrtf(icm45686.gyro_x * icm45686.gyro_x +
                                  icm45686.gyro_y * icm45686.gyro_y +
                                  icm45686.gyro_z * icm45686.gyro_z);

            // 3. 가속도와 각속도가 동시에 임계값을 넘는지 확인
            if (accel_mag >= ACCEL_IMPACT_THRESHOLD_G && gyro_mag >= GYRO_IMPACT_THRESHOLD_DPS) {
                uint32_t now = HAL_GetTick();
                if (now - last_impact_ms >= IMPACT_DEBOUNCE_MS) {
                    last_impact_ms = now;
                    printf("SEPARATION DETECTED! Accel: %.2f G, Gyro: %.2f dps\n\n", accel_mag, gyro_mag);
                }
            }
        }
        else {
            osDelay(1);
        }
    }
  /* USER CODE END StartIMU_Task */
}

void StartGPS_Task(void *argument)
{
  /* USER CODE BEGIN StartGPS_Task */
	M10S_TransmitData(&UBX_CFG_PRT[0], sizeof(UBX_CFG_PRT));
	osDelay(200);
	M10S_TransmitData(&UBX_CFG_MSG[0], sizeof(UBX_CFG_MSG));
	osDelay(200);
	M10S_TransmitData(&UBX_CFG_RATE[0], sizeof(UBX_CFG_RATE));
	osDelay(200);
	M10S_TransmitData(&UBX_CFG_CFG[0], sizeof(UBX_CFG_CFG));

  /* Infinite loop */
  for(;;)
  {
	  if(m10s_rx_cplt_flag == 1) {
		  m10s_rx_cplt_flag = 0;

		  if(ubx_checksum(&m10s_rx_buf[0], 36) == 1) {
			  M10S_UBX_POSLLH_Parsing(&m10s_rx_buf[0], &gps);
		  }
	  }
    osDelay(100);
  }
  /* USER CODE END StartGPS_Task */
}

void StartMS5611_Task(void *argument)
{
  /* USER CODE BEGIN StartMS5611_Task */
	float launch_pad_pressure_hpa = 0.0f;

	// 고도 값 보정
	for (int i = 0; i < 20; i++) {
		if (ms5611_basic_read(&ms5611.temp, &ms5611.pressure_mbar) == 0)
			launch_pad_pressure_hpa += ms5611.pressure_mbar;
	}

	launch_pad_pressure_hpa = launch_pad_pressure_hpa / 20;

	/* Infinite loop */
	for (;;) {
		if (ms5611_basic_read(&ms5611.temp, &ms5611.pressure_mbar) == 0) {
			ms5611.altitude = 44330.0f *(1.0f - pow(ms5611.pressure_mbar / launch_pad_pressure_hpa, 1.0f / 5.255f));
		}
		osDelay(1);
	}
  /* USER CODE END StartMS5611_Task */
}

void StartINA219_Task(void *argument)
{
  /* USER CODE BEGIN StartINA219_Task */
	/* Infinite loop */
	for (;;) {
		ina219_main.bus_voltage_mv = INA219_ReadBusVoltage(&ina219_main) + 790;
		ina219_main.current = INA219_ReadCurrent(&ina219_main);         // mA 단위
		ina219_main.power = INA219_ReadPower(&ina219_main) / 10;        // mW 단위
		ina219_main.battery_level = INA219_GetBatteryLife(&ina219_main, 8400,
				6000);

		ina219_ign.bus_voltage_mv = INA219_ReadBusVoltage(&ina219_ign);
		ina219_ign.current = INA219_ReadCurrent(&ina219_ign) / 1000;
		ina219_ign.power = INA219_ReadPower(&ina219_ign) / 1000;
		ina219_ign.battery_level = INA219_GetBatteryLife(&ina219_ign, 12600,
				9000);

		osDelay(100);
	}
  /* USER CODE END StartINA219_Task */
}

void StartReadTemp_Task(void *argument)
{
  /* USER CODE BEGIN StartReadTemp_Task */
	/* Infinite loop */
	for (;;) {
		for (int i = 0; i < NUM_SENSORS; i++) {
			AS6221_ReadTemperature(&as6221[i]);
			osDelay(10);
		}

		CPU_Temp = (float) __HAL_ADC_CALC_TEMPERATURE(3300, adc3_val[0],
				ADC_RESOLUTION_12B) / 100.0f;

		osDelay(100);
	}
  /* USER CODE END StartReadTemp_Task */
}

void StartMainTask(void *argument)
{
  /* USER CODE BEGIN StartMainTask */
	uint16_t Decoupling_alt = 0;
	uint16_t Max_alt = 0;
  /* Infinite loop */
  for(;;) {
    // 1. 대회용 로켓 발사 (StartMainTask 진입 시 이미 발사된 것으로 가정)

    // 2. CanSAT 발사체로부터 사출 (고도 400m 이상에서 분리)
    if (Decoupling_flag) {
    	Decoupling_flag = false;

    	Decoupling_alt = ms5611.altitude;

    	if(Decoupling_alt > ms5611.altitude + 20) {
    		HAL_GPIO_WritePin(GPIOE, GPIO_PIN_10, GPIO_PIN_SET); // 솔레노이드 HIGH (아답터 분리)
    		osDelay(1000); // 솔레노이드 작동 시간
    		HAL_GPIO_WritePin(GPIOE, GPIO_PIN_10, GPIO_PIN_RESET); // 솔레노이드 LOW

    		 hyperion_separated = true;
    	}
    }

    // 5. 아답터와 일정 거리 떨어진 후 2차 추진제 점화 (고도센서가 200m 이하일 경우 그냥 점화)
    if (hyperion_separated && !second_propellant_ignited) {
      if (ms5611.altitude <= 200 || forceING) { // 고도 200m 이하일 경우
        HAL_GPIO_WritePin(GPIOE, GPIO_PIN_7, GPIO_PIN_SET); // 고체연료 점화 HIGH
        osDelay(15000); // 최대 15초간 On
        HAL_GPIO_WritePin(GPIOE, GPIO_PIN_7, GPIO_PIN_RESET); // 고체연료 점화 LOW
        second_propellant_ignited = true;
      }
    }

    if(Max_alt < ms5611.altitude)
    	Max_alt = ms5611.altitude;

    if(Max_alt > ms5611.altitude + 30 || (ms5611.altitude < 200 && hyperion_separated)) {
    	HAL_GPIO_WritePin(GPIOE, GPIO_PIN_11, GPIO_PIN_RESET);
    	HAL_GPIO_WritePin(GPIOE, GPIO_PIN_12, GPIO_PIN_RESET);
    }
    osDelay(1);

  }
  /* USER CODE END StartMainTask */
}

/* USER CODE BEGIN Application */
void HAL_UART_RxCpltCallback(UART_HandleTypeDef *huart) {
	static unsigned char cnt = 0;

	if (huart->Instance == USART3) {
		HAL_UART_Receive_IT(&huart3, &rx3_data, 1);
//		HAL_UART_Transmit(&huart8, &rx3_data, 1, 100);

		switch(cnt) {
		case 0:
			if(rx3_data == 0xb5) {
				m10s_rx_buf[cnt] = rx3_data;
				cnt++;
			}
			break;
		case 1:
			if(rx3_data == 0x62) {
				m10s_rx_buf[cnt] = rx3_data;
				cnt++;
			}
			else
				cnt = 0;
			break;
		case 35:
			m10s_rx_buf[cnt] = rx3_data;
			cnt = 0;
			m10s_rx_cplt_flag = 1;
			break;
		default:
			m10s_rx_buf[cnt] = rx3_data;
			cnt++;
			break;
		}
	}
	if(huart->Instance == USART3) {
		HAL_UART_Receive_IT(&huart1, &rx1_data, 1);

		if(rx1_data == 'D') {
			Decoupling_flag = true;
			HAL_GPIO_TogglePin(LD1_GPIO_Port, LD1_Pin);
		}
		if(rx1_data == 'I') {
			forceING = true;
			HAL_GPIO_TogglePin(LD2_GPIO_Port, LD2_Pin);
		}
	}
}

void M10S_TransmitData(unsigned char* data, unsigned len) {
	for(int i = 0; i < len; i++) {
		HAL_UART_Transmit(&huart3, &data[i], 1, 100);
	}
}

uint8_t ubx_checksum(uint8_t *payload, uint16_t length) {
	uint8_t a = 0, b = 0;

	for (uint16_t i = 2; i < length - 2; i++) {
		a = a + payload[i];
		b = b + a;
	}

	return(a == payload[length - 2]) && (b == payload[length - 1]);
}

void M10S_UBX_POSLLH_Parsing(unsigned char* data, gpsData* gps) {
	gps->CLASS = data[2];
	gps->ID = data[3];
	gps->LENGTH = data[4] | data[5] << 8;

	gps->iTOW = data[6] | data[7] << 8 | data[8] << 16 | data[9] << 24;
	gps->lon = data[10] | data[11] << 8 | data[12] << 16 | data[13] <<24;
	gps->lat = data[14] | data[15] << 8 | data[16] << 16 | data[17] <<24;
	gps->height = data[18] | data[19] << 8 | data[20] << 16 | data[21] <<24;
	gps->hMSL = data[22] | data[23] << 8 | data[24] << 16 | data[25] <<24;
	gps->hAcc = data[26] | data[27] << 8 | data[28] << 16 | data[29] <<24;
	gps->vAcc = data[30] | data[31] << 8 | data[32] << 16 | data[33] <<24;

	gps->lon_f64 = gps->lon  / 10000000.;
	gps->lat_f64 = gps->lat  / 10000000.;
}

uint16_t CRC16_CCITT(const uint8_t *data, uint16_t length)
{
    uint16_t crc = 0xFFFF;

    while (length--)
    {
        crc ^= (uint16_t)(*data++) << 8;  // 상위바이트부터 XOR
        for (uint8_t i = 0; i < 8; i++)
            crc = (crc & 0x8000) ? (crc << 1) ^ 0x1021
                                 : (crc << 1);
    }
    return crc;
}

void CRC16_CCITT_Split(const uint8_t *data, uint16_t length,
                       uint8_t *high, uint8_t *low)
{
    uint16_t crc = CRC16_CCITT(data, length);
    *high = (uint8_t)(crc >> 8);
    *low  = (uint8_t)(crc & 0xFF);
}

/* USER CODE END Application */
